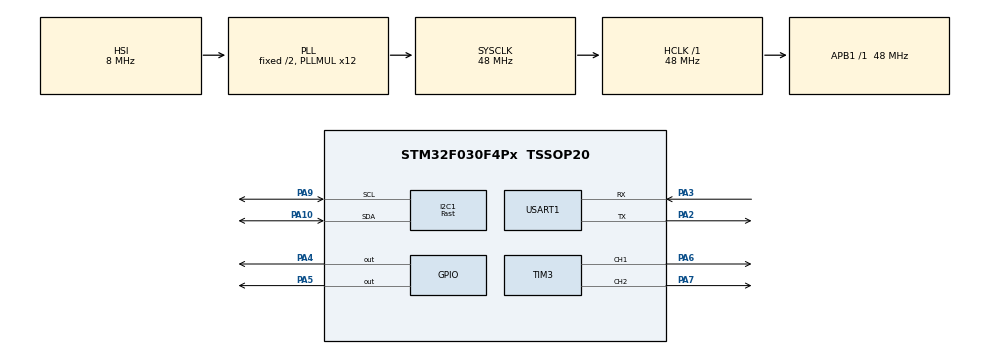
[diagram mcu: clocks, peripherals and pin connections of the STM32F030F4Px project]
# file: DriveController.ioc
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Dma.I2C1_RX.0.Direction=DMA_PERIPH_TO_MEMORY
Dma.I2C1_RX.0.Instance=DMA1_Channel3
Dma.I2C1_RX.0.MemDataAlignment=DMA_MDATAALIGN_BYTE
Dma.I2C1_RX.0.MemInc=DMA_MINC_ENABLE
Dma.I2C1_RX.0.Mode=DMA_NORMAL
Dma.I2C1_RX.0.PeriphDataAlignment=DMA_PDATAALIGN_BYTE
Dma.I2C1_RX.0.PeriphInc=DMA_PINC_DISABLE
Dma.I2C1_RX.0.Priority=DMA_PRIORITY_LOW
Dma.Request0=I2C1_RX
I2C1.I2C_Speed_Mode=I2C_Fast
I2C1.Timing=0x2010091A
Mcu.Family=STM32F0
Mcu.Name=STM32F030F4Px
Mcu.Package=TSSOP20
NVIC.DMA1_Channel2_3_IRQn=true\:0\:0\:false\:false\:true\:false\:true\:true
PA10.Mode=I2C
PA10.Signal=I2C1_SDA
PA13.Mode=Serial_Wire
PA13.Signal=SYS_SWDIO
PA14.Mode=Serial_Wire
PA14.Signal=SYS_SWCLK
PA2.Mode=Asynchronous
PA2.Signal=USART1_TX
PA3.Mode=Asynchronous
PA3.Signal=USART1_RX
PA4.Signal=GPIO_Output
PA5.Signal=GPIO_Output
PA6.Signal=S_TIM3_CH1
PA7.Signal=S_TIM3_CH2
PA9.Mode=I2C
PA9.Signal=I2C1_SCL
ProjectManager.HeapSize=0x200
ProjectManager.StackSize=0x400
ProjectManager.TargetToolchain=STM32CubeIDE
RCC.AHBFreq_Value=48000000
RCC.APB1Freq_Value=48000000
RCC.APB1TimFreq_Value=48000000
RCC.HCLKFreq_Value=48000000
RCC.I2c1ClockSelection=RCC_I2C1CLKSOURCE_SYSCLK
RCC.PLLMUL=RCC_PLL_MUL12
RCC.SYSCLKFreq_VALUE=48000000
RCC.SYSCLKSource=RCC_SYSCLKSOURCE_PLLCLK
SH.S_TIM3_CH1.0=TIM3_CH1,PWM Generation1 CH1
SH.S_TIM3_CH2.0=TIM3_CH2,PWM Generation2 CH2
TIM3.Channel-PWM\ Generation1\ CH1=TIM_CHANNEL_1
TIM3.Channel-PWM\ Generation2\ CH2=TIM_CHANNEL_2
USART1.VirtualMode-Asynchronous=VM_ASYNC
VP_TIM14_VS_ClockSourceINT.Mode=Enable_Timer
VP_TIM1_VS_ClockSourceINT.Mode=Internal
VP_TIM3_VS_ClockSourceINT.Mode=Internal
board=custom

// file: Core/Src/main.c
/* USER CODE BEGIN Header */
/**
  ******************************************************************************
  * @file           : main.c
  * @brief          : Main program body
  ******************************************************************************
  * @attention
  *
  * Copyright (c) 2023 STMicroelectronics.
  * All rights reserved.
  *
  * This software is licensed under terms that can be found in the LICENSE file
  * in the root directory of this software component.
  * If no LICENSE file comes with this software, it is provided AS-IS.
  *
  ******************************************************************************
  */
/* USER CODE END Header */
#include "main.h"
#include "dma.h"
#include "i2c.h"
#include "tim.h"
#include "usart.h"
#include "gpio.h"

/* USER CODE BEGIN Includes */
#include "bsp_as5600.h"
//#include "INA219.h"
#include "lib_ina219.h"

/* USER CODE END Includes */

void SystemClock_Config(void);

/* USER CODE BEGIN 0 */
//I2C_HandleTypeDef hi2c1;

//INA219_t ina219;
float data, raw ;

uint16_t vbus, vshunt, current, config, power;
/* USER CODE END 0 */

int main(void)
{

  /* MCU Configuration--------------------------------------------------------*/

  /* Reset of all peripherals, Initializes the Flash interface and the Systick. */
  HAL_Init();

  /* Configure the system clock */
  SystemClock_Config();

  /* Initialize all configured peripherals */
  MX_GPIO_Init();
  MX_DMA_Init();
  MX_I2C1_Init();
  MX_TIM1_Init();
  MX_USART1_UART_Init();
  MX_TIM3_Init();
  MX_TIM14_Init();
  /* USER CODE BEGIN 2 */
  HAL_GPIO_WritePin(GPIOA, GPIO_PIN_4, GPIO_PIN_SET);
  HAL_GPIO_WritePin(GPIOA, GPIO_PIN_5, GPIO_PIN_SET);
  bsp_as5600Init();
	HAL_Delay(100);

	ina219_SetCalibration_16V_80mA();
  //while(!INA219_Init(&ina219, &hi2c1, INA219_ADDRESS))

  /* USER CODE END 2 */

  /* Infinite loop */
  /* USER CODE BEGIN WHILE */
  while (1)
  {
	  uint16_t  angle_raw = bsp_as5600GetRawAngle();
	  //current = INA219_ReadCurrent(&ina219);

	  HAL_GPIO_WritePin(GPIOA, GPIO_PIN_5,angle_raw<1000);
	  HAL_GPIO_TogglePin(GPIOA, GPIO_PIN_4);

	 // HAL_GPIO_WritePin(GPIOA, GPIO_PIN_4, GPIO_PIN_SET);
	  HAL_Delay(1000);
	 // HAL_GPIO_WritePin(GPIOA, GPIO_PIN_4, GPIO_PIN_RESET);
	 // HAL_Delay(500);
    /* USER CODE END WHILE */

  }
}

void SystemClock_Config(void)
{
  RCC_OscInitTypeDef RCC_OscInitStruct = {0};
  RCC_ClkInitTypeDef RCC_ClkInitStruct = {0};
  RCC_PeriphCLKInitTypeDef PeriphClkInit = {0};

  /** Initializes the RCC Oscillators according to the specified parameters
  * in the RCC_OscInitTypeDef structure.
  */
  RCC_OscInitStruct.OscillatorType = RCC_OSCILLATORTYPE_HSI;
  RCC_OscInitStruct.HSIState = RCC_HSI_ON;
  RCC_OscInitStruct.HSICalibrationValue = RCC_HSICALIBRATION_DEFAULT;
  RCC_OscInitStruct.PLL.PLLState = RCC_PLL_ON;
  RCC_OscInitStruct.PLL.PLLSource = RCC_PLLSOURCE_HSI;
  RCC_OscInitStruct.PLL.PLLMUL = RCC_PLL_MUL12;
  RCC_OscInitStruct.PLL.PREDIV = RCC_PREDIV_DIV1;
  if (HAL_RCC_OscConfig(&RCC_OscInitStruct) != HAL_OK)
  {
    Error_Handler();
  }

  /** Initializes the CPU, AHB and APB buses clocks
  */
  RCC_ClkInitStruct.ClockType = RCC_CLOCKTYPE_HCLK|RCC_CLOCKTYPE_SYSCLK
                              |RCC_CLOCKTYPE_PCLK1;
  RCC_ClkInitStruct.SYSCLKSource = RCC_SYSCLKSOURCE_PLLCLK;
  RCC_ClkInitStruct.AHBCLKDivider = RCC_SYSCLK_DIV1;
  RCC_ClkInitStruct.APB1CLKDivider = RCC_HCLK_DIV1;

  if (HAL_RCC_ClockConfig(&RCC_ClkInitStruct, FLASH_LATENCY_1) != HAL_OK)
  {
    Error_Handler();
  }
  PeriphClkInit.PeriphClockSelection = RCC_PERIPHCLK_USART1|RCC_PERIPHCLK_I2C1;
  PeriphClkInit.Usart1ClockSelection = RCC_USART1CLKSOURCE_PCLK1;
  PeriphClkInit.I2c1ClockSelection = RCC_I2C1CLKSOURCE_SYSCLK;
  if (HAL_RCCEx_PeriphCLKConfig(&PeriphClkInit) != HAL_OK)
  {
    Error_Handler();
  }
}

void Error_Handler(void)
{
  __disable_irq();
  while (1)
  {
  }
}
